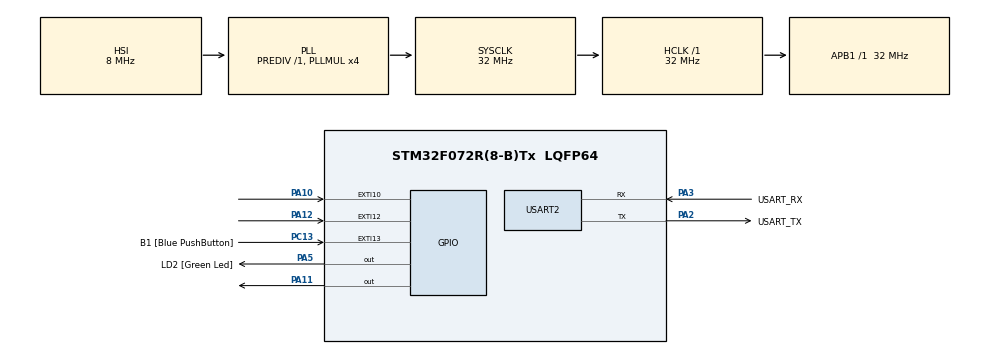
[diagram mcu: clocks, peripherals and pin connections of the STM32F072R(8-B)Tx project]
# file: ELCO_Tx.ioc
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Mcu.Family=STM32F0
Mcu.Name=STM32F072R(8-B)Tx
Mcu.Package=LQFP64
NVIC.EXTI4_15_IRQn=true\:0\:0\:false\:false\:true\:true\:true
PA10.GPIO_ModeDefaultEXTI=GPIO_MODE_IT_RISING_FALLING
PA10.Signal=GPXTI10
PA11.Signal=GPIO_Output
PA12.GPIO_PuPd=GPIO_NOPULL
PA12.Signal=GPXTI12
PA13.GPIO_Label=TMS
PA13.Mode=Serial_Wire
PA13.Signal=SYS_SWDIO
PA14.GPIO_Label=TCK
PA14.Mode=Serial_Wire
PA14.Signal=SYS_SWCLK
PA2.GPIO_Label=USART_TX
PA2.GPIO_Mode=GPIO_MODE_AF_PP
PA2.GPIO_PuPd=GPIO_NOPULL
PA2.GPIO_Speed=GPIO_SPEED_FREQ_LOW
PA2.Mode=Asynchronous
PA2.Signal=USART2_TX
PA3.GPIO_Label=USART_RX
PA3.GPIO_Mode=GPIO_MODE_AF_PP
PA3.GPIO_PuPd=GPIO_NOPULL
PA3.GPIO_Speed=GPIO_SPEED_FREQ_LOW
PA3.Mode=Asynchronous
PA3.Signal=USART2_RX
PA5.GPIO_Label=LD2 [Green Led]
PA5.GPIO_Mode=GPIO_MODE_OUTPUT_PP
PA5.GPIO_PuPd=GPIO_NOPULL
PA5.GPIO_Speed=GPIO_SPEED_FREQ_LOW
PA5.Signal=GPIO_Output
PC13.GPIO_Label=B1 [Blue PushButton]
PC13.GPIO_ModeDefaultEXTI=GPIO_MODE_IT_FALLING
PC13.Signal=GPXTI13
PC14-OSC32_IN.Mode=LSE-External-Oscillator
PC14-OSC32_IN.Signal=RCC_OSC32_IN
PC15-OSC32_OUT.Mode=LSE-External-Oscillator
PC15-OSC32_OUT.Signal=RCC_OSC32_OUT
PF0-OSC_IN.Mode=HSE-External-Clock-Source
PF0-OSC_IN.Signal=RCC_OSC_IN
PF1-OSC_OUT.Signal=RCC_OSC_OUT
ProjectManager.HeapSize=0x200
ProjectManager.StackSize=0x400
ProjectManager.TargetToolchain=STM32CubeIDE
RCC.AHBFreq_Value=32000000
RCC.APB1Freq_Value=32000000
RCC.APB1TimFreq_Value=32000000
RCC.FLatency-AdvancedSettings=FLASH_LATENCY_1
RCC.HCLKFreq_Value=32000000
RCC.PLLMUL=RCC_PLL_MUL4
RCC.PREFETCH_ENABLE-AdvancedSettings=1
RCC.SYSCLKFreq_VALUE=32000000
RCC.SYSCLKSource=RCC_SYSCLKSOURCE_PLLCLK
TIM15.Period=7999
TIM15.Prescaler=2
USART2.VirtualMode=VM_ASYNC
USART2.VirtualMode-Asynchronous=VM_ASYNC
VP_TIM15_VS_ClockSourceINT.Mode=Internal
board=NUCLEO-F072RB

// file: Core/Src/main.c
/* USER CODE BEGIN Header */
/**
  ******************************************************************************
  * @file           : main.c
  * @brief          : Main program body
  ******************************************************************************
  * @attention
  *
  * <h2><center>&copy; Copyright (c) 2020 STMicroelectronics.
  * All rights reserved.</center></h2>
  *
  * This software component is licensed by ST under BSD 3-Clause license,
  * the "License"; You may not use this file except in compliance with the
  * License. You may obtain a copy of the License at:
  *                        opensource.org/licenses/BSD-3-Clause
  *
  ******************************************************************************
  */
/* USER CODE END Header */

#include "main.h"

TIM_HandleTypeDef htim15;

UART_HandleTypeDef huart2;

/* USER CODE BEGIN PV */
uint8_t count=0;
uint8_t data1[4]={1,0,1,0};
/* USER CODE END PV */

void SystemClock_Config(void);
static void MX_GPIO_Init(void);
static void MX_USART2_UART_Init(void);
static void MX_TIM15_Init(void);

int main(void)
{

  /* MCU Configuration--------------------------------------------------------*/

  /* Reset of all peripherals, Initializes the Flash interface and the Systick. */
  HAL_Init();

  /* Configure the system clock */
  SystemClock_Config();

  /* Initialize all configured peripherals */
  MX_GPIO_Init();
  MX_USART2_UART_Init();
  MX_TIM15_Init();

  /* Infinite loop */
  while (1)
  {

  }
}

void SystemClock_Config(void)
{
  RCC_OscInitTypeDef RCC_OscInitStruct = {0};
  RCC_ClkInitTypeDef RCC_ClkInitStruct = {0};
  RCC_PeriphCLKInitTypeDef PeriphClkInit = {0};

  /** Initializes the CPU, AHB and APB busses clocks
  */
  RCC_OscInitStruct.OscillatorType = RCC_OSCILLATORTYPE_HSI;
  RCC_OscInitStruct.HSIState = RCC_HSI_ON;
  RCC_OscInitStruct.HSICalibrationValue = RCC_HSICALIBRATION_DEFAULT;
  RCC_OscInitStruct.PLL.PLLState = RCC_PLL_ON;
  RCC_OscInitStruct.PLL.PLLSource = RCC_PLLSOURCE_HSI;
  RCC_OscInitStruct.PLL.PLLMUL = RCC_PLL_MUL4;
  RCC_OscInitStruct.PLL.PREDIV = RCC_PREDIV_DIV1;
  if (HAL_RCC_OscConfig(&RCC_OscInitStruct) != HAL_OK)
  {
    Error_Handler();
  }
  /** Initializes the CPU, AHB and APB busses clocks
  */
  RCC_ClkInitStruct.ClockType = RCC_CLOCKTYPE_HCLK|RCC_CLOCKTYPE_SYSCLK
                              |RCC_CLOCKTYPE_PCLK1;
  RCC_ClkInitStruct.SYSCLKSource = RCC_SYSCLKSOURCE_PLLCLK;
  RCC_ClkInitStruct.AHBCLKDivider = RCC_SYSCLK_DIV1;
  RCC_ClkInitStruct.APB1CLKDivider = RCC_HCLK_DIV1;

  if (HAL_RCC_ClockConfig(&RCC_ClkInitStruct, FLASH_LATENCY_1) != HAL_OK)
  {
    Error_Handler();
  }
  PeriphClkInit.PeriphClockSelection = RCC_PERIPHCLK_USART2;
  PeriphClkInit.Usart2ClockSelection = RCC_USART2CLKSOURCE_PCLK1;
  if (HAL_RCCEx_PeriphCLKConfig(&PeriphClkInit) != HAL_OK)
  {
    Error_Handler();
  }
}

static void MX_TIM15_Init(void)
{

  TIM_ClockConfigTypeDef sClockSourceConfig = {0};
  TIM_MasterConfigTypeDef sMasterConfig = {0};

  htim15.Instance = TIM15;
  htim15.Init.Prescaler = 2;
  htim15.Init.CounterMode = TIM_COUNTERMODE_UP;
  htim15.Init.Period = 7999;
  htim15.Init.ClockDivision = TIM_CLOCKDIVISION_DIV1;
  htim15.Init.RepetitionCounter = 0;
  htim15.Init.AutoReloadPreload = TIM_AUTORELOAD_PRELOAD_DISABLE;
  if (HAL_TIM_Base_Init(&htim15) != HAL_OK)
  {
    Error_Handler();
  }
  sClockSourceConfig.ClockSource = TIM_CLOCKSOURCE_INTERNAL;
  if (HAL_TIM_ConfigClockSource(&htim15, &sClockSourceConfig) != HAL_OK)
  {
    Error_Handler();
  }
  sMasterConfig.MasterOutputTrigger = TIM_TRGO_RESET;
  sMasterConfig.MasterSlaveMode = TIM_MASTERSLAVEMODE_DISABLE;
  if (HAL_TIMEx_MasterConfigSynchronization(&htim15, &sMasterConfig) != HAL_OK)
  {
    Error_Handler();
  }

}

static void MX_USART2_UART_Init(void)
{

  huart2.Instance = USART2;
  huart2.Init.BaudRate = 38400;
  huart2.Init.WordLength = UART_WORDLENGTH_8B;
  huart2.Init.StopBits = UART_STOPBITS_1;
  huart2.Init.Parity = UART_PARITY_NONE;
  huart2.Init.Mode = UART_MODE_TX_RX;
  huart2.Init.HwFlowCtl = UART_HWCONTROL_NONE;
  huart2.Init.OverSampling = UART_OVERSAMPLING_16;
  huart2.Init.OneBitSampling = UART_ONE_BIT_SAMPLE_DISABLE;
  huart2.AdvancedInit.AdvFeatureInit = UART_ADVFEATURE_NO_INIT;
  if (HAL_UART_Init(&huart2) != HAL_OK)
  {
    Error_Handler();
  }

}

static void MX_GPIO_Init(void)
{
  GPIO_InitTypeDef GPIO_InitStruct = {0};

  /* GPIO Ports Clock Enable */
  __HAL_RCC_GPIOC_CLK_ENABLE();
  __HAL_RCC_GPIOF_CLK_ENABLE();
  __HAL_RCC_GPIOA_CLK_ENABLE();

  /*Configure GPIO pin Output Level */
  HAL_GPIO_WritePin(GPIOA, LD2_Pin|GPIO_PIN_11, GPIO_PIN_RESET);

  /*Configure GPIO pin : B1_Pin */
  GPIO_InitStruct.Pin = B1_Pin;
  GPIO_InitStruct.Mode = GPIO_MODE_IT_FALLING;
  GPIO_InitStruct.Pull = GPIO_NOPULL;
  HAL_GPIO_Init(B1_GPIO_Port, &GPIO_InitStruct);

  /*Configure GPIO pins : LD2_Pin PA11 */
  GPIO_InitStruct.Pin = LD2_Pin|GPIO_PIN_11;
  GPIO_InitStruct.Mode = GPIO_MODE_OUTPUT_PP;
  GPIO_InitStruct.Pull = GPIO_NOPULL;
  GPIO_InitStruct.Speed = GPIO_SPEED_FREQ_LOW;
  HAL_GPIO_Init(GPIOA, &GPIO_InitStruct);

  /*Configure GPIO pin : PA10 */
  GPIO_InitStruct.Pin = GPIO_PIN_10;
  GPIO_InitStruct.Mode = GPIO_MODE_IT_RISING_FALLING;
  GPIO_InitStruct.Pull = GPIO_NOPULL;
  HAL_GPIO_Init(GPIOA, &GPIO_InitStruct);

  /*Configure GPIO pin : PA12 */
  GPIO_InitStruct.Pin = GPIO_PIN_12;
  GPIO_InitStruct.Mode = GPIO_MODE_IT_RISING;
  GPIO_InitStruct.Pull = GPIO_NOPULL;
  HAL_GPIO_Init(GPIOA, &GPIO_InitStruct);

  /* EXTI interrupt init*/
  HAL_NVIC_SetPriority(EXTI4_15_IRQn, 0, 0);
  HAL_NVIC_EnableIRQ(EXTI4_15_IRQn);

}

/* USER CODE BEGIN 4 */

void HAL_GPIO_EXTI_Callback(uint16_t GPIO_Pin) {

	//Interrupcion externa realizada con la pulsacion de un boton
	if(GPIO_Pin == GPIO_PIN_12){
		HAL_TIM_Base_Start_IT(&htim15); // Start del timer como interrupción de 1ms
	}

	if(GPIO_Pin == GPIO_PIN_10){
		HAL_GPIO_WritePin(GPIOA, GPIO_PIN_5, HAL_GPIO_ReadPin(GPIOA, GPIO_PIN_10));
	}
}

void HAL_TIM_PeriodElapsedCallback(TIM_HandleTypeDef *htim){

	if (htim == &htim15){
		count++;
		//Pa probar que todo OK envio por UART
		HAL_UART_Transmit(&huart2, data1, 4, 1000);
		//Escribo en el pin el valor del array en cada interrupcion de 1ms
		HAL_GPIO_WritePin(GPIOA, GPIO_PIN_11, data1[count]);

		//Cuando llego a mas de 4 paro el timer
		if(count>4){
			HAL_TIM_Base_Stop_IT(&htim15);
		}
	}
}

/* USER CODE END 4 */

void Error_Handler(void)
{
}

/************************ (C) COPYRIGHT STMicroelectronics *****END OF FILE****/
